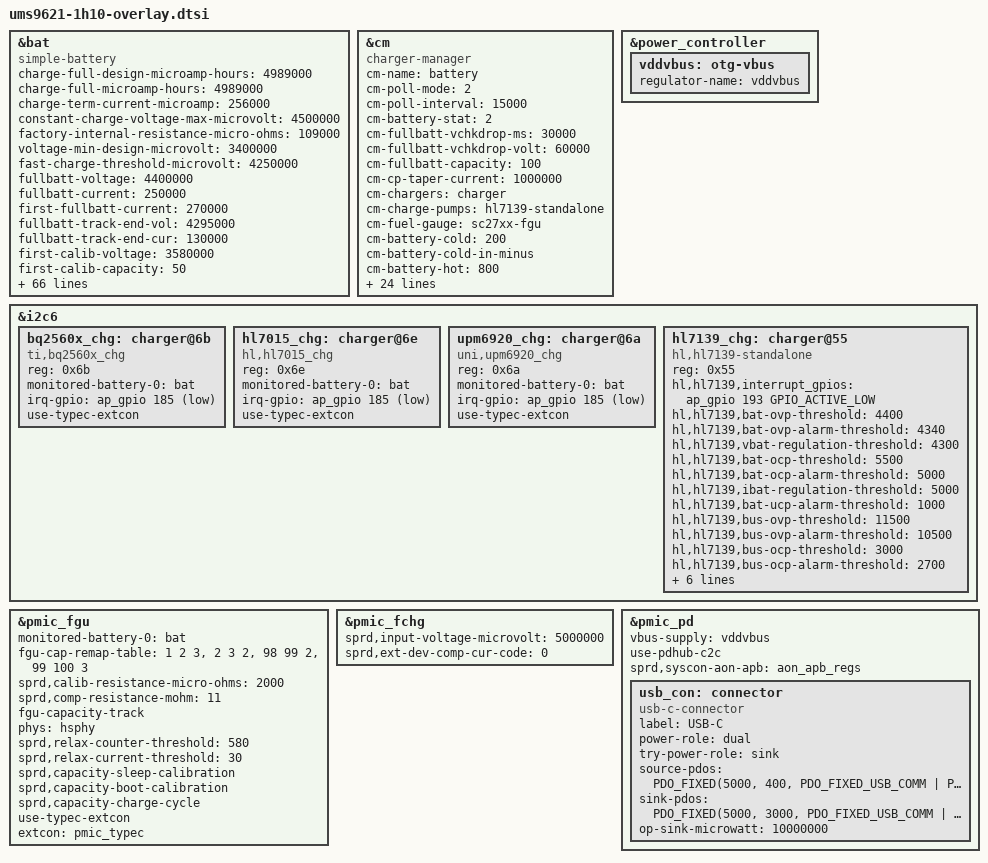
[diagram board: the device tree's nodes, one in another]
// SPDX-License-Identifier: (Licenseref-Unisoc-General-1.0 OR GPL-2.0-only)
/*
 * ums9621-1h10-overlay.dtsi - Unisoc platform device
 *
 * Copyright 2022 Unisoc(Shanghai) Technologies Co.Ltd
 *
 * Licensed under the Unisoc General Software License, version 1.0 (the
 * License);
 * you may not use this file except in compliance with the License.
 * You may obtain a copy of the License at
 * https://www.unisoc.com/en_us/license/UNISOC_GENERAL_LICENSE_V1.0-EN_US
 * Software distributed under the License is distributed on an "AS IS" BASIS,
 * WITHOUT WARRANTIES OF ANY KIND, either express or implied.
 * See the Unisoc General Software License, version 1.0 for more details.
 *
 * Alternatively you can use and distribute this file under the terms of the
 * GNU General Public License version 2, provided that it has to be used
 *  (including but not limited to combining, linking) with any other file under
 * the GNU General Public License version 2 on platforms that use Unisoc Chips.
 */

#include <dt-bindings/usb/pd.h>

&bat {
	compatible = "simple-battery";
	status = "okay";
	charge-full-design-microamp-hours = <4989000>;
	charge-full-microamp-hours = <4989000>;
	charge-term-current-microamp = <256000>;
	constant-charge-voltage-max-microvolt = <4500000>;
	factory-internal-resistance-micro-ohms = <109000>;
	voltage-min-design-microvolt = <3400000>;
	fast-charge-threshold-microvolt = <4250000>;
	fullbatt-voltage = <4400000>;
	fullbatt-current = <250000>;
	first-fullbatt-current = <270000>;

	fullbatt-track-end-vol = <4295000>;
	fullbatt-track-end-cur = <130000>;
	first-calib-voltage = <3580000>;
	first-calib-capacity = <50>;
	batt-ovp-threshold-microvolt = <4800000>;

	ir-cv-offset-microvolt = <100000>;
	ir-rc-micro-ohms = <10000>;
	ir-us-upper-limit-microvolt = <4576000>;

	ocv-capacity-celsius = <25>;
	ocv-capacity-table-0 = <4449000 100>, <4382000 95>, <4328000 90>,
				<4270000 85>, <4210000 80>, <4151000 75>,
				<4095000 70>, <4043000 65>, <3997000 60>,
				<3948000 55>, <3890000 50>, <3859000 45>,
				<3835000 40>, <3815000 35>, <3799000 30>,
				<3779000 25>, <3755000 20>, <3731000 15>,
				<3698000 10>, <3689000 5>, <3400000 0>;
	voltage-temp-table = <1307000 700>, <1203000 750>, <1095000 800>, <986000 850>, <878000 900>,
	      <775000 950>, <678000 1000>, <590000 1050>,
	      <510000 1100>, <440000 1150>, <378000 1200>,
	      <324000 1250>, <278000 1300>, <238000 1350>,
	      <204000 1400>, <175000 1450>, <150000 1500>,
	      <129000 1550>, <111000 1600>, <96000 1650> , <83000 1700>,<63000 1800>;
	capacity-temp-table = <45 100>, <25 100>, <10 100>, <0 92>, <(-10) 84>;
	resistance-temp-table = <45 86>, <25 100>, <10 165>, <0 1067>, <(-10) 1184>;
//	temp-advance-fullcap-table = <50 100>, <25 100>, <10 100>, <0 100>,
//		<(-10) 100>, <(-20) 100>;

	charge-sdp-current-microamp = <600000 500000>;
	charge-dcp-current-microamp = <2200000 2100000>;
	charge-cdp-current-microamp = <1500000 1500000>;
	charge-unknown-current-microamp = <1050000 1050000>;
	charge-fchg-current-microamp = <4000000 2200000>;
	charge-flash-current-microamp = <6000000 3000000>;

	cap-calib-energy-density-ocv-table = <3350000 3800000>, <4150000 4350000>;
	cap-track-energy-density-ocv-table = <3400000 3722000>;

	dcp-jeita-temp-table = <1000 1030 0 4340000>, <1150 1180 700000 4500000>,
		<1450 1420 2000000 4500000>, <1600 1570 700000 4100000>;
	sdp-jeita-temp-table = <1000 1030 0 4340000>, <1150 1180 500000 4500000>,
		<1450 1420 500000 4500000>, <1600 1570 500000 4100000>;
	cdp-jeita-temp-table = <1000 1030 0 4340000>, <1150 1180 700000 4500000>,
		<1450 1420 1500000 4500000>, <1600 1570 700000 4100000>;
	unknown-jeita-temp-table = <1000 1030 0 4340000>, <1150 1180 700000 4500000>,
		<1450 1420 1050000 4500000>, <1600 1570 700000 4100000>;
	fchg-jeita-temp-table = <1000 1030 0 4340000>, <1150 1180 700000 4500000>,
		<1450 1420 4000000 4544000>, <1600 1570 700000 4100000>;
	flash-jeita-temp-table = <1000 1020 0 4340000>, <1050 1070 500000 4340000>,
		<1120 1140 1000000 4340000>, <1160 1180 1500000 4340000>,
		<1220 1240 4500000 4340000>, <1340 1360 5000000 4340000>,
		<1370 1350 5000000 4340000>, <1400 1380 4500000 4340000>,
		<1420 1400 4250000 4340000>, <1450 1430 4000000 4340000>,
		<1600 1570 1000000 4100000>;
};

&cm {
	compatible = "charger-manager";
	status = "okay";
	cm-name = "battery";
	cm-poll-mode = <2>;
	cm-poll-interval = <15000>;
	cm-battery-stat = <2>;

	cm-fullbatt-vchkdrop-ms = <30000>;
	cm-fullbatt-vchkdrop-volt = <60000>;
	cm-fullbatt-capacity = <100>;
	/*Charge pump target charge current*/
	cm-cp-taper-current = <1000000>;

	cm-chargers = "charger";
	cm-charge-pumps = "hl7139-standalone";
	cm-fuel-gauge = "sc27xx-fgu";

	/* in deci centigrade */
	cm-battery-cold = <200>;
	cm-battery-cold-in-minus;
	cm-battery-hot = <800>;
	cm-battery-temp-diff = <100>;

	/* Allow charging for 6hr */
	cm-charging-max = <21600000>;
	/* recovery charging after stop charging 45min */
	cm-discharging-max = <2700000>;

	/* the interval to feed charger watchdog */
	cm-wdt-interval = <60>;

	/* drop voltage in microVolts to allow shutdown */
	cm-shutdown-voltage = <3100000>;

	/* when 99% of the time is exceeded, it will be forced to 100% */
	cm-tickle-time-out = <1500>;

	/* how much time to allow capacity change */
	cm-one-cap-time = <30>;

	cm-thermal-zone = "board-thmzone";

	/* when the safe charging voltage is exceeded, stop charging */
	cm-charge-voltage-max = <6500000>;
	cm-fast-charge-voltage-max = <10500000>;
	cm-flash-charge-voltage-max = <12000000>;
	/* drop voltage in microVolts to restart charging */
	cm-charge-voltage-drop = <700000>;
	cm-fast-charge-voltage-drop = <700000>;
	cm-flash-charge-voltage-drop = <1000000>;

	/* sprd_fchg parameter */
	sprd,support-fchg;
	sprd,pd-fixed-max-microwatt = <27000000>;

	monitored-battery-0 = <&bat>;
	cm-capacity-track;
	cm-keep-awake;
	cm-support-linear-charge;

	phys = <&hsphy>;
	pd-extcon-enable;
	extcon = <&pmic_typec>, <&pmic_pd>;
	use-typec-extcon;

};

&power_controller {
	vddvbus:otg-vbus {
		regulator-name = "vddvbus";
	};
};

&i2c6 {
	#address-cells = <1>;
	#size-cells = <0>;

	status = "okay";
	bq2560x_chg: charger@6b {
		compatible = "ti,bq2560x_chg";
		reg = <0x6b>;
		monitored-battery-0 = <&bat>;
		irq-gpio = <&ap_gpio 185 GPIO_ACTIVE_LOW>;
		use-typec-extcon;
	};
	hl7015_chg: charger@6e {
		compatible = "hl,hl7015_chg";
		reg = <0x6e>;
		monitored-battery-0 = <&bat>;
		irq-gpio = <&ap_gpio 185 GPIO_ACTIVE_LOW>;
		use-typec-extcon;
	};
	upm6920_chg: charger@6a {
		compatible = "uni,upm6920_chg";
		reg = <0x6a>;
		monitored-battery-0 = <&bat>;
		irq-gpio = <&ap_gpio 185 GPIO_ACTIVE_LOW>;
		use-typec-extcon;
	};

	hl7139_chg: charger@55 {
		compatible = "hl,hl7139-standalone";
		reg = <0x55>;
		hl,hl7139,interrupt_gpios = <&ap_gpio 193 GPIO_ACTIVE_LOW>;

		hl,hl7139,bat-ovp-threshold = <4400>;
		hl,hl7139,bat-ovp-alarm-threshold = <4340>;
		hl,hl7139,vbat-regulation-threshold = <4300>;

		hl,hl7139,bat-ocp-threshold = <5500>;
		hl,hl7139,bat-ocp-alarm-threshold = <5000>;
		hl,hl7139,ibat-regulation-threshold = <5000>;
		hl,hl7139,bat-ucp-alarm-threshold = <1000>;

		hl,hl7139,bus-ovp-threshold = <11500>;
		hl,hl7139,bus-ovp-alarm-threshold = <10500>;
		hl,hl7139,bus-ocp-threshold = <3000>;
		hl,hl7139,bus-ocp-alarm-threshold = <2700>;

		hl,hl7139,ac-ovp-threshold = <13>;

		hl,hl7139,die-tmp-reg-threshold = <100>;

		hl,hl7139,track-ov-delta-threshold = <900>;
		hl,hl7139,track-uv-delta-threshold = <250>;

		hl,hl7139,watchdog-timer = <30000>;

		hl,hl7139,sense-resistor-mohm = <2>;
	};
};

&pmic_fgu {
	monitored-battery-0 = <&bat>;
	fgu-cap-remap-table = <1 2 3>, <2 3 2>, <98 99 2>, <99 100 3>;
	sprd,calib-resistance-micro-ohms = <2000>;
	sprd,comp-resistance-mohm = <11>;

	fgu-capacity-track;
	phys = <&hsphy>;

	sprd,relax-counter-threshold = <580>;
	sprd,relax-current-threshold = <30>;
	sprd,capacity-sleep-calibration;

	sprd,capacity-boot-calibration;
	sprd,capacity-charge-cycle;
	use-typec-extcon;
	extcon = <&pmic_typec>;
};

&pmic_fchg {
	status = "okay";
	sprd,input-voltage-microvolt = <5000000>;

	/* External device current compensation code value during sfcp handshaking */
	sprd,ext-dev-comp-cur-code = <0>;
};

&pmic_pd {
	status = "okay";
	vbus-supply = <&vddvbus>;
	use-pdhub-c2c;
	sprd,syscon-aon-apb = <&aon_apb_regs>;
	usb_con: connector {
		compatible = "usb-c-connector";
		label = "USB-C";
		power-role = "dual";
		try-power-role = "sink";
		source-pdos = <PDO_FIXED(5000, 400, PDO_FIXED_USB_COMM |
			       PDO_FIXED_DUAL_ROLE | PDO_FIXED_DATA_SWAP)>;
		sink-pdos = <PDO_FIXED(5000, 3000, PDO_FIXED_USB_COMM |
			     PDO_FIXED_DUAL_ROLE | PDO_FIXED_DATA_SWAP)
			     PDO_PPS_APDO(3300, 11000, 3000)>;
		op-sink-microwatt = <10000000>;
	};
};
